# CPSW1_NUSS register map
Vendor: Texas Instruments
Peripheral module from a debugger description file (folder J721S2).
Registers are 32-bit, read-write, reset 0x0 unless marked. A register's access mark holds for its fields unless they carry their own. Offsets are as the file gives them; lines under a group give offsets from that group; [hi:lo] are bit positions; {n}, {i} and the like mark numbered series; 'fields as' and 'values as' point back to an identical list; <NAME> marks a mode.

## CPSW1_NUSS (part 1 of 2)
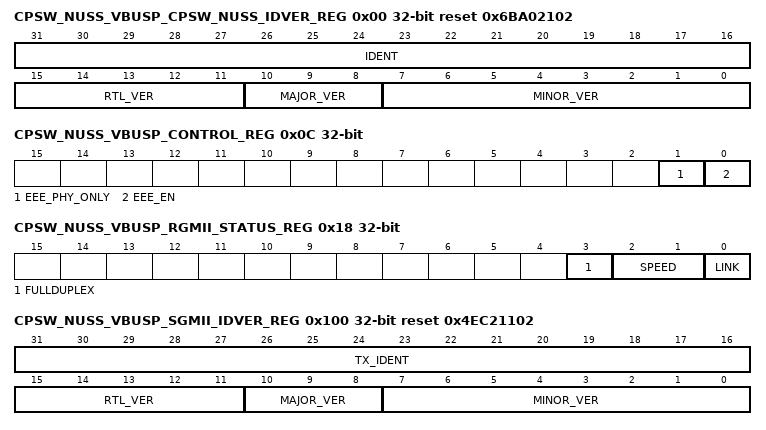
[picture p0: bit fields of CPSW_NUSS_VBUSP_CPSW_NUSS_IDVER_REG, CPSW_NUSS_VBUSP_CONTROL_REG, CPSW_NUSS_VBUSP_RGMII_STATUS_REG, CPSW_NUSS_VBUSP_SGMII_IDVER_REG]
0x00 CPSW_NUSS_VBUSP_CPSW_NUSS_IDVER_REG ro reset 0x6BA02102 — CPSW_NUSS ID Version Register
  [31:16] IDENT — Identification value
  [15:11] RTL_VER — RTL version value
  [10:8] MAJOR_VER — Major version value
  [7:0] MINOR_VER — Minor version value
0x04 CPSW_NUSS_VBUSP_SYNCE_COUNT_REG — CPSW_NUSS SYNCE Count Register
  [31:0] SYNCE_CNT — Sync E Count Value
0x08 CPSW_NUSS_VBUSP_SYNCE_MUX_REG — CPSW_NUSS Synce Mux Register
  [5:0] SYNCE_SEL — Sync E Select Value
0x0C CPSW_NUSS_VBUSP_CONTROL_REG — CPSW_NUSS Control Register
  [1] EEE_PHY_ONLY — Energy Efficient Enable Phy Only Mode: 0=The low power indicate state includes gating off the CPPI_GCLK to the CPSW, 1=The low power indicate state does not gate the clock to the CPSW
  [0] EEE_EN — Energy Efficient Ethernet Enable: 0=EEE is disabled, 1=EEE is enabled
0x10 CPSW_NUSS_VBUSP_SGMII_MODE_REG reset 0x1 — CPSW_NUSS SyncE Mux Register
  [0] SYNCE_SEL — SGMII_MODE Input
0x18 CPSW_NUSS_VBUSP_RGMII_STATUS_REG ro — CPSW_NUSS RGMII Status Register
  [3] FULLDUPLEX — Rgmii full dulex: 0=Half-duplex, 1=Full-duplex
  [2:1] SPEED — Rgmii speed: 00=10Mbps, 01=100Mbps, 10=1000Mbps, 11=reserved
  [0] LINK — Rgmii link indicator: 0=Link is down, 1=Link is up
0x1C CPSW_NUSS_VBUSP_SUBSSYSTEM_STATUS_REG ro — CPSW_NUSS Status Register
  [0] EEE_CLKSTOP_ACK — Energy Efficient Ethernet clockstop acknowledge from CPSW
0x100 CPSW_NUSS_VBUSP_SGMII_IDVER_REG ro reset 0x4EC21102 — SGMII IDVER register
  [31:16] TX_IDENT — Module value
  [15:11] RTL_VER — RTL version value
  [10:8] MAJOR_VER — Major version value
  [7:0] MINOR_VER — Minor version value
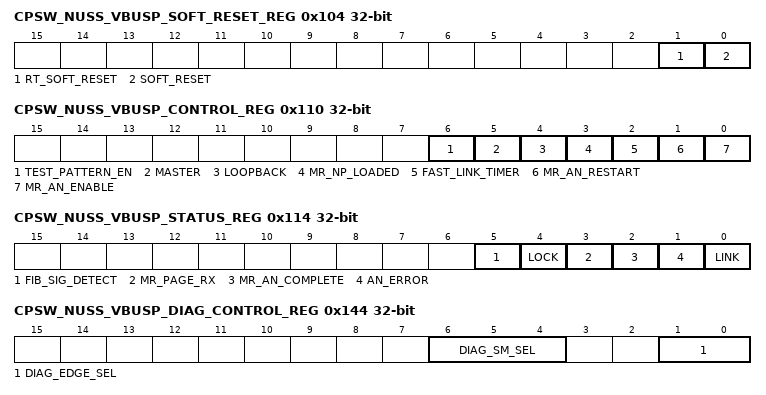
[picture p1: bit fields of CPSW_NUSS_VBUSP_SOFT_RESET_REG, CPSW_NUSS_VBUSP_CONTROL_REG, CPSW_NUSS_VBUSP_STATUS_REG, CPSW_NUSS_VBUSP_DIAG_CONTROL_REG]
0x104 CPSW_NUSS_VBUSP_SOFT_RESET_REG — SGMII Soft Reset Register
  [1] RT_SOFT_RESET — Transmit and receive software reset
  [0] SOFT_RESET — Software reset
0x110 CPSW_NUSS_VBUSP_CONTROL_REG — SGMII Control Register
  [6] TEST_PATTERN_EN — Test pattern enable
  [5] MASTER — Master mode
  [4] LOOPBACK — Loopback mode
  [3] MR_NP_LOADED — Next page loaded
  [2] FAST_LINK_TIMER
  [1] MR_AN_RESTART — Auto-negotiation restart
  [0] MR_AN_ENABLE — Auto-negotiation enable
0x114 CPSW_NUSS_VBUSP_STATUS_REG ro — SGMII Status Register
  [5] FIB_SIG_DETECT — Fiber signal detect
  [4] LOCK
  [3] MR_PAGE_RX — Next page received
  [2] MR_AN_COMPLETE — Auto-negotiation complete
  [1] AN_ERROR — Auto-negotiation error
  [0] LINK — Link indicator
0x118 CPSW_NUSS_VBUSP_MR_ADV_ABILITY_REG — SGMII MR Advertized Ability Register
  [15:0] MR_ADV_ABILITY — Advertised ability
0x11C CPSW_NUSS_VBUSP_MR_NP_TX_REG — SGMII Next Pate Transmit Register
  [15:0] MR_NP_TX — Next page transmit
0x120 CPSW_NUSS_VBUSP_MR_LP_ADV_ABILITY_REG ro — SGMII Link Partner Advertized Ability Register
  [15:0] MR_LP_ADV_ABILITY — Link partner advertised ability
0x124 CPSW_NUSS_VBUSP_MR_LP_NP_RX_REG ro — SGMII Link Partner Next Page Receive Register
  [15:0] MR_LP_NP_RX — Link Partner Next Page Received
0x130 CPSW_NUSS_VBUSP_TX_CFG_REG — SGMII Transmit Configuration Register
  [31:0] TX_CFG — Transmit configuration register output
0x134 CPSW_NUSS_VBUSP_RX_CFG_REG — SGMII Receive Configuration Register
  [31:0] RX_CFG — Receive configuration register output
0x138 CPSW_NUSS_VBUSP_AUX_CFG_REG — SGMII Auxiliary Configuration Register
  [31:0] AUX_CFG — Auxiliary configuration register output
0x140 CPSW_NUSS_VBUSP_DIAG_CLEAR_REG — SGMII Diagnostics Clear Register
  [0] DIAG_CLEAR — Diagnostics clear
0x144 CPSW_NUSS_VBUSP_DIAG_CONTROL_REG — SGMII Diagnostics Control Register
  [6:4] DIAG_SM_SEL — Diagnostic select
  [1:0] DIAG_EDGE_SEL — Diagnostics hold signals edge select
0x148 CPSW_NUSS_VBUSP_DIAG_STATUS_REG ro — SGMII Diagnostics Status Register
  [15:0] DIAG_STATUS — Diagnostics status
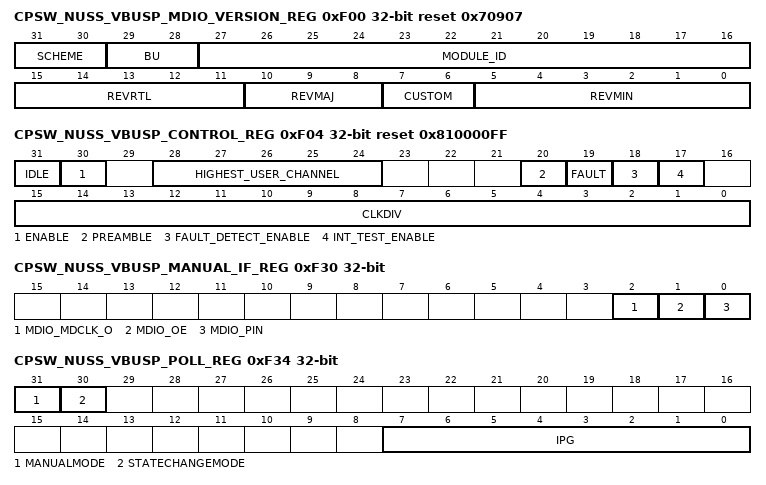
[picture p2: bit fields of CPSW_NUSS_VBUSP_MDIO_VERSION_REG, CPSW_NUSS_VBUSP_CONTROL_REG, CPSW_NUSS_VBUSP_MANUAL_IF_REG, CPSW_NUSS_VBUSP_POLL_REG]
0xF00 CPSW_NUSS_VBUSP_MDIO_VERSION_REG ro reset 0x70907 — MDIO Version Register
  [31:30] SCHEME
  [29:28] BU
  [27:16] MODULE_ID
  [15:11] REVRTL — RTL version
  [10:8] REVMAJ — Major version
  [7:6] CUSTOM — Custom version
  [5:0] REVMIN — Minor version
0xF04 CPSW_NUSS_VBUSP_CONTROL_REG access per field reset 0x810000FF — MDIO Control Register
  [31] IDLE ro — MDIO state machine idle
  [30] ENABLE rw — Enable control
  [28:24] HIGHEST_USER_CHANNEL ro
  [20] PREAMBLE rw — Preamble disable
  [19] FAULT rw — Fault indicator
  [18] FAULT_DETECT_ENABLE rw
  [17] INT_TEST_ENABLE rw — Interrupt test enable
  [15:0] CLKDIV rw — Clock divider
0xF08 CPSW_NUSS_VBUSP_ALIVE_REG — MDIO Alive Register
  [31:0] ALIVE — MDIO alive
0xF0C CPSW_NUSS_VBUSP_LINK_REG ro — MDIO Link Register
  [31:0] LINK — MDIO link state
0xF10 CPSW_NUSS_VBUSP_LINK_INT_RAW_REG — MDIO Link Interrupt Raw Register
  [1:0] LINKINTRAW — MDIO link change event raw value
0xF14 CPSW_NUSS_VBUSP_LINK_INT_MASKED_REG — MDIO Link Interrupt Masked Register
  [1:0] LINKINTMASKED — MDIO link change interrupt masked value
0xF18 CPSW_NUSS_VBUSP_LINK_INT_MASK_SET_REG — MDIO Link Interrupt Mask Set Register
  [0] LINKINTMASKSET — MDIO link interrupt mask set
0xF1C CPSW_NUSS_VBUSP_LINK_INT_MASK_CLEAR_REG — MDIO Link Interrupt Mask Clear Register
  [0] LINKINTMASKCLR — MDIO link interrupt mask clear
0xF20 CPSW_NUSS_VBUSP_USER_INT_RAW_REG — MDIO User Interrupt Raw Register
  [1:0] USERINTRAW — User interrupt raw
0xF24 CPSW_NUSS_VBUSP_USER_INT_MASKED_REG — MDIO User Interrupt Masked Register
  [1:0] USERINTMASKED — User interrupt masked
0xF28 CPSW_NUSS_VBUSP_USER_INT_MASK_SET_REG — MDIO User Interrupt Mask Set Register
  [1:0] USERINTMASKSET — MDIO user interrupt mask set
0xF2C CPSW_NUSS_VBUSP_USER_INT_MASK_CLEAR_REG — MDIO User Interrupt Mask Clear Register
  [1:0] USERINTMASKCLR — MDIO user interrupt mask clear
0xF30 CPSW_NUSS_VBUSP_MANUAL_IF_REG — MDIO Manual Interface Register
  [2] MDIO_MDCLK_O — MDIO Clock Output
  [1] MDIO_OE — MDIO Output Enable
  [0] MDIO_PIN
0xF34 CPSW_NUSS_VBUSP_POLL_REG — MDIO Poll Register
  [31] MANUALMODE — MDIO Manual Mode
  [30] STATECHANGEMODE — MDIO State Change Mode
  [7:0] IPG — MDIO IPG
0xF38 CPSW_NUSS_VBUSP_POLL_EN_REG reset 0xFFFFFFFF — MDIO Poll Enable Register
  [31:0] POLL_EN — MDIO Poll Enable
0xF3C CPSW_NUSS_VBUSP_CLAUS45_REG — MDIO Clause45 Register
  [31:0] CLAUSE45 — MDIO Clause 45
0xF40 CPSW_NUSS_VBUSP_USER_ADDR0_REG — MDIO Address 0 Register
  [15:0] USER_ADDR0 — MDIO USER Address 0
0xF44 CPSW_NUSS_VBUSP_USER_ADDR1_REG — MDIO Address 1 Register
  [15:0] USER_ADDR1 — MDIO USER Address 1
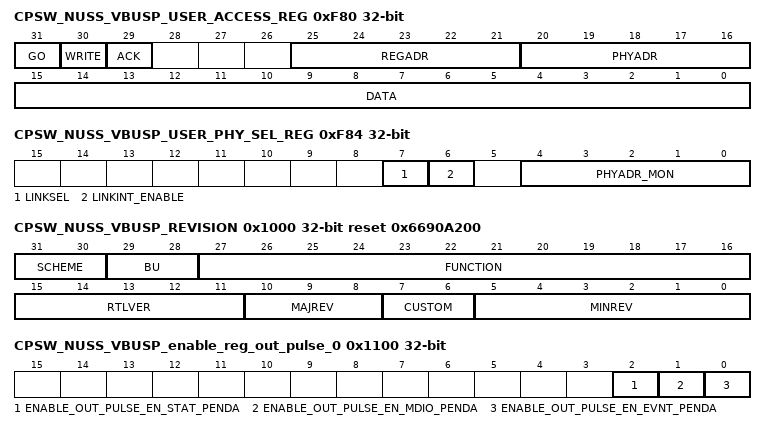
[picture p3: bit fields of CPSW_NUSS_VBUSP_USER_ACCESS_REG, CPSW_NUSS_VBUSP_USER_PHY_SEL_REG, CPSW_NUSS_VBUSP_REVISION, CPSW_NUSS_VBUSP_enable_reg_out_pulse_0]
0xF80 CPSW_NUSS_VBUSP_USER_ACCESS_REG — MDIO User Access Register
  [31] GO
  [30] WRITE
  [29] ACK — Acknowledge
  [25:21] REGADR — Register address
  [20:16] PHYADR — PHY address
  [15:0] DATA — User data
0xF84 CPSW_NUSS_VBUSP_USER_PHY_SEL_REG — MDIO User PHY Select Register
  [7] LINKSEL — Link status determination select
  [6] LINKINT_ENABLE — Link change interrupt enable
  [4:0] PHYADR_MON — PHY address whose link status is monitored
0x1000 CPSW_NUSS_VBUSP_REVISION ro reset 0x6690A200 — Revision Register
  [31:30] SCHEME
  [29:28] BU
  [27:16] FUNCTION — Module ID
  [15:11] RTLVER — RTL revisions
  [10:8] MAJREV — Major revision
  [7:6] CUSTOM — Custom revision
  [5:0] MINREV — Minor revision
0x1010 CPSW_NUSS_VBUSP_eoi_reg — End of Interrupt Register
  [7:0] EOI_VECTOR — End of Interrupt Vector
0x1014 CPSW_NUSS_VBUSP_intr_vector_reg ro — Interrupt Vector Register
  [31:0] INTR_VECTOR
0x1100 CPSW_NUSS_VBUSP_enable_reg_out_pulse_0 access not given — Enable Register 0
  [2] ENABLE_OUT_PULSE_EN_STAT_PENDA — Enable Set for out_pulse_en_stat_penda (access R/W1TS)
  [1] ENABLE_OUT_PULSE_EN_MDIO_PENDA — Enable Set for out_pulse_en_mdio_penda (access R/W1TS)
  [0] ENABLE_OUT_PULSE_EN_EVNT_PENDA — Enable Set for out_pulse_en_evnt_penda (access R/W1TS)
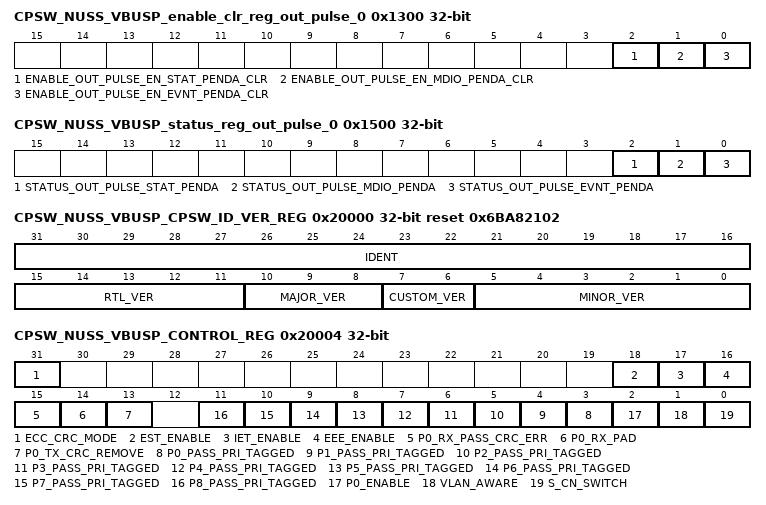
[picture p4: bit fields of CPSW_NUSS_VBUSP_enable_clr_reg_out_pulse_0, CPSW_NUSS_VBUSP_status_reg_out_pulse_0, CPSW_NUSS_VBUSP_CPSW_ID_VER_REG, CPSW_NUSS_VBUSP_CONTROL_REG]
0x1300 CPSW_NUSS_VBUSP_enable_clr_reg_out_pulse_0 access not given — Enable Clear Register 0
  [2] ENABLE_OUT_PULSE_EN_STAT_PENDA_CLR — Enable Clear for out_pulse_en_stat_penda (access R/W1TC)
  [1] ENABLE_OUT_PULSE_EN_MDIO_PENDA_CLR — Enable Clear for out_pulse_en_mdio_penda (access R/W1TC)
  [0] ENABLE_OUT_PULSE_EN_EVNT_PENDA_CLR — Enable Clear for out_pulse_en_evnt_penda (access R/W1TC)
0x1500 CPSW_NUSS_VBUSP_status_reg_out_pulse_0 ro — Status Register 0
  [2] STATUS_OUT_PULSE_STAT_PENDA — Status for out_pulse_en_stat_penda
  [1] STATUS_OUT_PULSE_MDIO_PENDA — Status for out_pulse_en_mdio_penda
  [0] STATUS_OUT_PULSE_EVNT_PENDA — Status for out_pulse_en_evnt_penda
0x1A80 CPSW_NUSS_VBUSP_intr_vector_reg_out_pulse ro — Interrupt Vector for out_pulse
  [31:0] INTR_VECTOR_OUT_PULSE — Interrupt Vector
0x20000 CPSW_NUSS_VBUSP_CPSW_ID_VER_REG ro reset 0x6BA82102 — CPSW ID Version
  [31:16] IDENT — Identification Value
  [15:11] RTL_VER — RTL Version Value
  [10:8] MAJOR_VER — Major Version Value
  [7:6] CUSTOM_VER — Custom Version Value
  [5:0] MINOR_VER — Minor Version Value
0x20004 CPSW_NUSS_VBUSP_CONTROL_REG — CPSW Switch Control
  [31] ECC_CRC_MODE
  [18] EST_ENABLE — Intersperced Express Traffic enable
  [17] IET_ENABLE — Intersperced Express Traffic enable
  [16] EEE_ENABLE — Energy Efficient Ethernet enable
  [15] P0_RX_PASS_CRC_ERR — Port 0 Pass Received CRC errors
  [14] P0_RX_PAD — Port 0 Receive Short Packet Pad
  [13] P0_TX_CRC_REMOVE — Port 0 Transmit CRC remove
  [n+3] P{n}_PASS_PRI_TAGGED (n=0..8) — Port {n} Pass Priority Tagged
  [2] P0_ENABLE — Port 0 Enable
  [1] VLAN_AWARE — VLAN Aware Mode
  [0] S_CN_SWITCH — VLAN Aware Mode
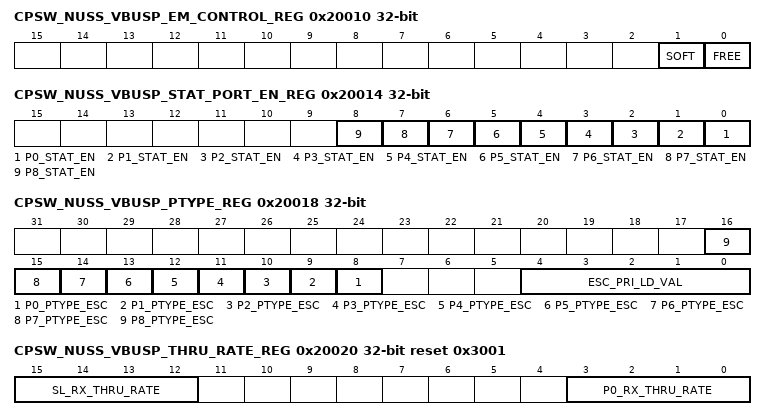
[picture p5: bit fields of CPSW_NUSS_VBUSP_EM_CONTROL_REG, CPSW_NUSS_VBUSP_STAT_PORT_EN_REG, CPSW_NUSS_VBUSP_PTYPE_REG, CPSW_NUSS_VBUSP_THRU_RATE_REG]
0x20010 CPSW_NUSS_VBUSP_EM_CONTROL_REG — CPSW Emulation Control
  [1] SOFT — Emulation Soft Bit
  [0] FREE — Emulation Free Bit
0x20014 CPSW_NUSS_VBUSP_STAT_PORT_EN_REG — CPSW Statistics Port Enable
  [n] P{n}_STAT_EN (n=0..8) — Port {n} Statistics Enable
0x20018 CPSW_NUSS_VBUSP_PTYPE_REG — CPSW Transmit Priority Type
  [n+8] P{n}_PTYPE_ESC (n=0..8) — Port {n} Priority Type Escalate
  [4:0] ESC_PRI_LD_VAL — Escalate Priority Load Value
0x2001C CPSW_NUSS_VBUSP_SOFT_IDLE_REG — CPSW Software Idle
  [0] SOFT_IDLE — Software Idle
0x20020 CPSW_NUSS_VBUSP_THRU_RATE_REG reset 0x3001 — CPSW Thru Rate
  [15:12] SL_RX_THRU_RATE — Switch FIFO receive through rate
  [3:0] P0_RX_THRU_RATE — CPPI FIFO receive through rate
0x20024 CPSW_NUSS_VBUSP_GAP_THRESH_REG reset 0xB — CPSW Transmit FIFO Short Gap Threshold
  [4:0] GAP_THRESH — Short Gap Threshold
0x20028 CPSW_NUSS_VBUSP_TX_START_WDS_REG reset 0x8 — CPSW Transmit FIFO Start Words
  [10:0] TX_START_WDS — FIFO Packet Transmit Start Words
0x2002C CPSW_NUSS_VBUSP_EEE_PRESCALE_REG — CPSW Energy Efficient Ethernet Prescale Value
  [11:0] EEE_PRESCALE — Energy Efficient Ethernet Pre-scale count load value
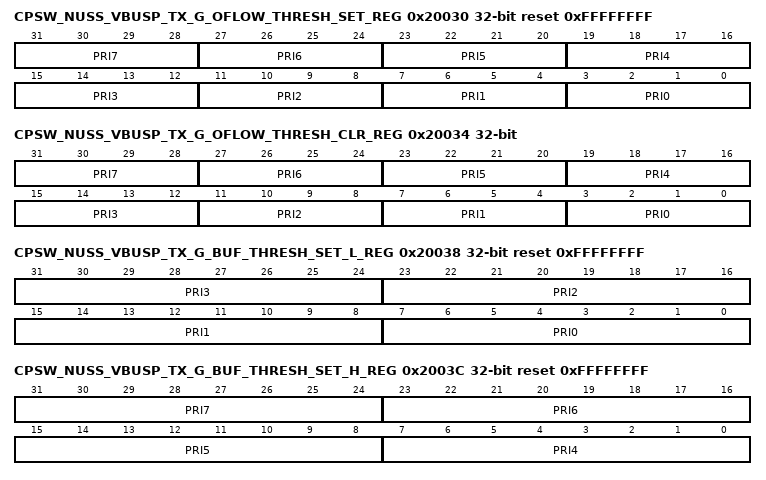
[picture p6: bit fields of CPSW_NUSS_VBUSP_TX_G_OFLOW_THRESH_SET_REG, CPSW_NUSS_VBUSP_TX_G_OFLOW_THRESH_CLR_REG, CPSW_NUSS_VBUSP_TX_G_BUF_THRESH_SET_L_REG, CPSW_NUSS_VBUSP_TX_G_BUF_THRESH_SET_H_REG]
0x20030 CPSW_NUSS_VBUSP_TX_G_OFLOW_THRESH_SET_REG reset 0xFFFFFFFF — CPSW PFC Tx Global Out Flow Threshold Set
  [4n+3:4n] PRI{n} (n=0..7) — Priority Based Flow Control Global Outflow Usage Threshold for Pri {n}
0x20034 CPSW_NUSS_VBUSP_TX_G_OFLOW_THRESH_CLR_REG — CPSW PFC Tx Global Out Flow Threshold Clear
  fields as CPSW_NUSS_VBUSP_TX_G_OFLOW_THRESH_SET_REG
0x20038 CPSW_NUSS_VBUSP_TX_G_BUF_THRESH_SET_L_REG reset 0xFFFFFFFF — CPSW PFC Global Tx Buffer Threshold Set Low
  [8n+7:8n] PRI{n} (n=0..3) — Priority Based Flow Control Global Buffer Usage Threshold for Priority {n}
0x2003C CPSW_NUSS_VBUSP_TX_G_BUF_THRESH_SET_H_REG reset 0xFFFFFFFF — CPSW PFC Global Tx Buffer Threshold Set High
  [8n-25:8n-32] PRI{n} (n=4..7) — Priority Based Flow Control Global Buffer Usage Threshold for Priority {n}
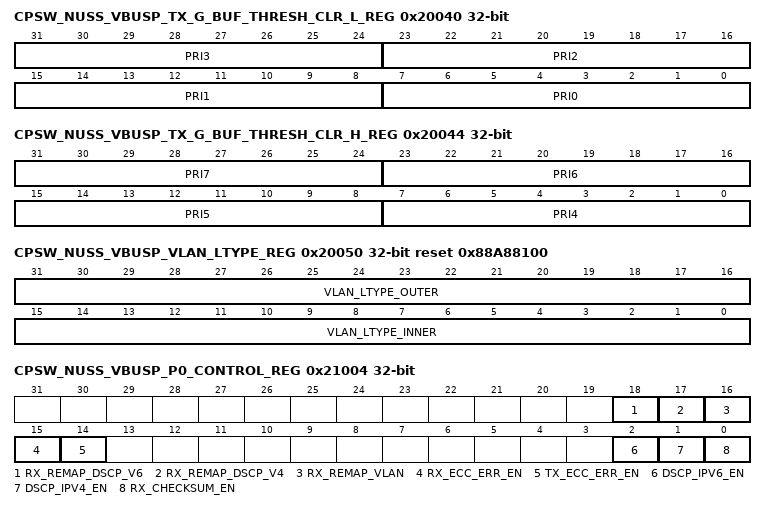
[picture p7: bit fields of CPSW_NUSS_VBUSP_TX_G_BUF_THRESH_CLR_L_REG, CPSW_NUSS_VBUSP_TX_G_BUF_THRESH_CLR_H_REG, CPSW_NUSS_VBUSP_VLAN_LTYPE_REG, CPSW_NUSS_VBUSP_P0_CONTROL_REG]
0x20040 CPSW_NUSS_VBUSP_TX_G_BUF_THRESH_CLR_L_REG — CPSW PFC Global Tx Buffer Threshold Clear Low
  fields as CPSW_NUSS_VBUSP_TX_G_BUF_THRESH_SET_L_REG
0x20044 CPSW_NUSS_VBUSP_TX_G_BUF_THRESH_CLR_H_REG — CPSW PFC Global Tx Buffer Threshold Clear High
  fields as CPSW_NUSS_VBUSP_TX_G_BUF_THRESH_SET_H_REG
0x20050 CPSW_NUSS_VBUSP_VLAN_LTYPE_REG reset 0x88A88100 — VLAN Length/type
  [31:16] VLAN_LTYPE_OUTER — Outer VLAN LType
  [15:0] VLAN_LTYPE_INNER — Inner VLAN LType
0x20054 CPSW_NUSS_VBUSP_EST_TS_DOMAIN_REG — Enhanced Scheduled Traffic Host Event Domain
  [7:0] EST_TS_DOMAIN
{0x20100+4i} CPSW_NUSS_VBUSP_TX_PRI{i}_MAXLEN_REG reset 0x7E8 (i=0..7) — Transmit Priority {i} Maximum Length
  [13:0] TX_PRI{i}_MAXLEN
0x21004 CPSW_NUSS_VBUSP_P0_CONTROL_REG — CPPI Port 0 Control
  [18] RX_REMAP_DSCP_V6 — Port 0 Remap DSCP_V6 Enable
  [17] RX_REMAP_DSCP_V4 — Port 0 Remap DSCP_V4 Enable
  [16] RX_REMAP_VLAN — Port 0 Remap VLAN Enable
  [15] RX_ECC_ERR_EN — Port 0 Receive ECC Error Enable
  [14] TX_ECC_ERR_EN — Port 0 Transmit ECC Error Enable
  [2] DSCP_IPV6_EN — Port 0 IPv6 DSCP enable
  [1] DSCP_IPV4_EN — Port 0 IPv4 DSCP enable
  [0] RX_CHECKSUM_EN — Port 0 Receive Checksum Enable
0x21008 CPSW_NUSS_VBUSP_P0_FLOW_ID_OFFSET_REG — CPPI Port 0 Flow ID Offset
  [13:0] VALUE — This value is added to the thread/Flow_ID in CPPI transmit PSI Info Word 0
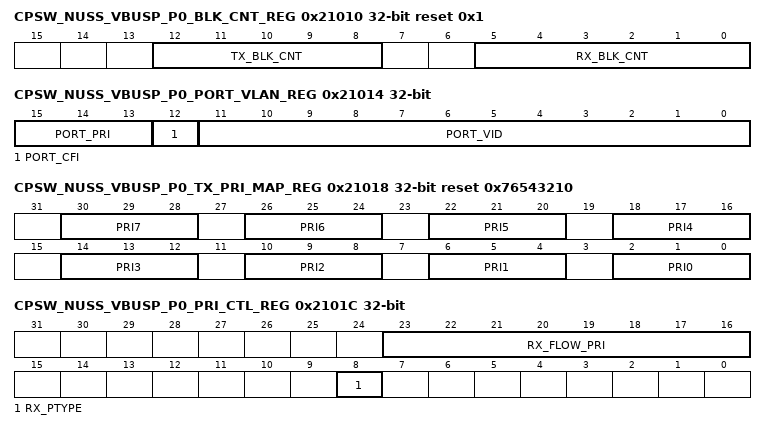
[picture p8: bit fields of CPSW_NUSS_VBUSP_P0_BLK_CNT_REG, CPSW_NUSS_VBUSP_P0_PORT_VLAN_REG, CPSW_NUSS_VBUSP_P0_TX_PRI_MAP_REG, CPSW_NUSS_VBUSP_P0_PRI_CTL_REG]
0x21010 CPSW_NUSS_VBUSP_P0_BLK_CNT_REG ro reset 0x1 — CPPI Port 0 FIFO Block Usage Count
  [12:8] TX_BLK_CNT — Port 0 Transmit Block Count Usage
  [5:0] RX_BLK_CNT — Port 0 Receive Block Count Usage
0x21014 CPSW_NUSS_VBUSP_P0_PORT_VLAN_REG — CPPI Port 0 VLAN
  [15:13] PORT_PRI — Port VLAN Priority
  [12] PORT_CFI — Port CFI bit
  [11:0] PORT_VID — Port VLAN ID
0x21018 CPSW_NUSS_VBUSP_P0_TX_PRI_MAP_REG reset 0x76543210 — CPPI Port 0 Tx Header Pri to Switch Pri Mapping
  [4n+2:4n] PRI{n} (n=0..7) — Priority {n}
0x2101C CPSW_NUSS_VBUSP_P0_PRI_CTL_REG — CPPI Port 0 Priority Control
  [23:16] RX_FLOW_PRI — Receive Priority Based Flow Control Enable (per priority)
  [8] RX_PTYPE — Receive Priority Type
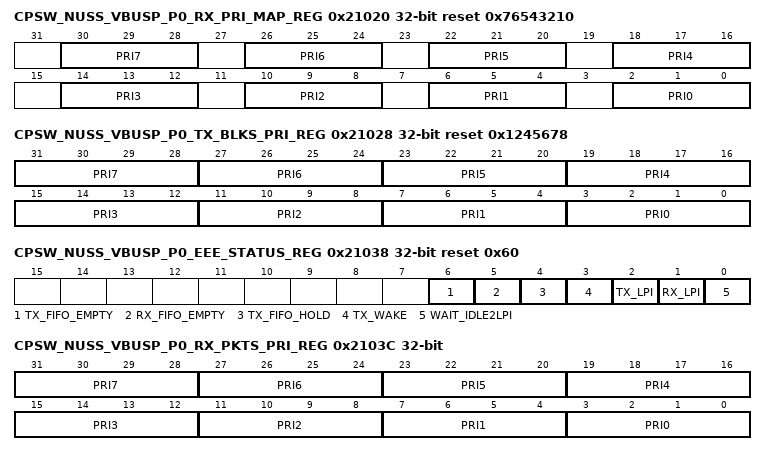
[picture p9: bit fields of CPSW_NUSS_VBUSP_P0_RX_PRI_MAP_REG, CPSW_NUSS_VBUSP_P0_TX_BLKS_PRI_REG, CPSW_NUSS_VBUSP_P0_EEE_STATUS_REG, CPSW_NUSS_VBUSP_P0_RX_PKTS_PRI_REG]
0x21020 CPSW_NUSS_VBUSP_P0_RX_PRI_MAP_REG reset 0x76543210 — CPPI Port 0 RX Pkt Pri to Header Pri Map
  [4n+2:4n] PRI{n} (n=0..7) — Priority {n}
0x21024 CPSW_NUSS_VBUSP_P0_RX_MAXLEN_REG reset 0x5EE — CPPI Port 0 Receive Frame Max Length
  [13:0] RX_MAXLEN — Rx Maximum Frame Length
0x21028 CPSW_NUSS_VBUSP_P0_TX_BLKS_PRI_REG reset 0x1245678 — CPPI Port 0 Transmit Block Sub Per Priority
  [4n+3:4n] PRI{n} (n=0..7) — Priority {n} Port Transmit Blocks
0x21030 CPSW_NUSS_VBUSP_P0_IDLE2LPI_REG — Port 0 EEE Idle to LPI counter
  [23:0] COUNT — Port 0 EEE Idle to LPI counter load value
0x21034 CPSW_NUSS_VBUSP_P0_LPI2WAKE_REG — Port 0 EEE LPI to wake counter
  [23:0] COUNT — Port 0 EEE LPI to wake counter load value
0x21038 CPSW_NUSS_VBUSP_P0_EEE_STATUS_REG ro reset 0x60 — Port 0 EEE status
  [6] TX_FIFO_EMPTY — CPPI port 0 transmit FIFO (switch egress) is empty - contains no packets
  [5] RX_FIFO_EMPTY — CPPI port 0 receive FIFO (switch ingress) is empty - contains no packets
  [4] TX_FIFO_HOLD — CPPI port 0 transmit FIFO hold - asserted in the LPI state and during the LPI2WAKE count time
  [3] TX_WAKE — CPPI port 0 transmit wakeup - asserted in the transmit LPI2WAKE count time
  [2] TX_LPI — CPPI port 0 transmit LPI state - asserted when the port 0 transmit is in the LPI state
  [1] RX_LPI — CPPI port 0 receive LPI state - asserted when the port 0 receive is in the LPI state
  [0] WAIT_IDLE2LPI — CPPI port 0 wait idle to LPI - asserted when port 0 is counting the IDLE2LPI time
0x2103C CPSW_NUSS_VBUSP_P0_RX_PKTS_PRI_REG — CPPI Port Receive Packets per priority
  [4n+3:4n] PRI{n} (n=0..7) — Priority {n} Port Port 0 Receive Packets
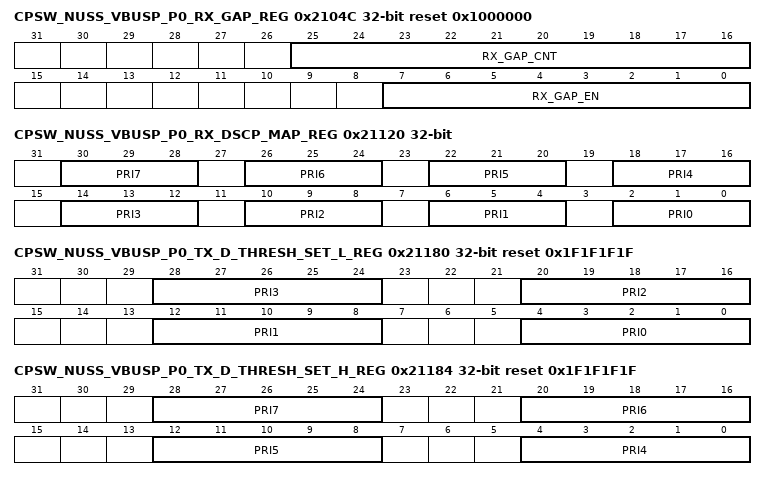
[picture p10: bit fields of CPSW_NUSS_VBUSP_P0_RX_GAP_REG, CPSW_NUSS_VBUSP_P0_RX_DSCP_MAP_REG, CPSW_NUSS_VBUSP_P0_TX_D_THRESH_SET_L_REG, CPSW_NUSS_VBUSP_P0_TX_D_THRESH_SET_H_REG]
0x2104C CPSW_NUSS_VBUSP_P0_RX_GAP_REG reset 0x1000000 — Port 0 Receive Gap Register
  [25:16] RX_GAP_CNT — Port 0 Receive Gap Count
  [7:0] RX_GAP_EN — Port 0 Receive Gap Enable
0x21050 CPSW_NUSS_VBUSP_P0_FIFO_STATUS_REG ro — Port 0 FIFO Status
  [7:0] TX_PRI_ACTIVE
0x21120 CPSW_NUSS_VBUSP_P0_RX_DSCP_MAP_REG — CPPI Port 0 Receive IPV4/IPV6 DSCP Map N
  [4n+2:4n] PRI{n} (n=0..7) — A DSCP IPV4/V6 packet TOS of N*8+{n} is mapped to this received priority
0x21140 CPSW_NUSS_VBUSP_P0_PRI_CIR_REG — CPPI Port 0 Rx Priority P Committed Information Rate
  [27:0] PRI_CIR — Priority N CIR
0x21160 CPSW_NUSS_VBUSP_P0_PRI_EIR_REG — CPPI Port 0 Rx Priority P Excess Information Rate
  [27:0] PRI_EIR — Priority N EIR
0x21180 CPSW_NUSS_VBUSP_P0_TX_D_THRESH_SET_L_REG reset 0x1F1F1F1F — CPPI Port 0 Tx PFC Destination Threshold Set Low
  [8n+4:8n] PRI{n} (n=0..3) — Port Priority Based Flow Control Threshold Set Value for Priority {n}
0x21184 CPSW_NUSS_VBUSP_P0_TX_D_THRESH_SET_H_REG reset 0x1F1F1F1F — CPPI Port 0 Tx PFC Destination Threshold Set High
  [8n-28:8n-32] PRI{n} (n=4..7) — Port Priority Based Flow Control Threshold Set Value for Priority {n}
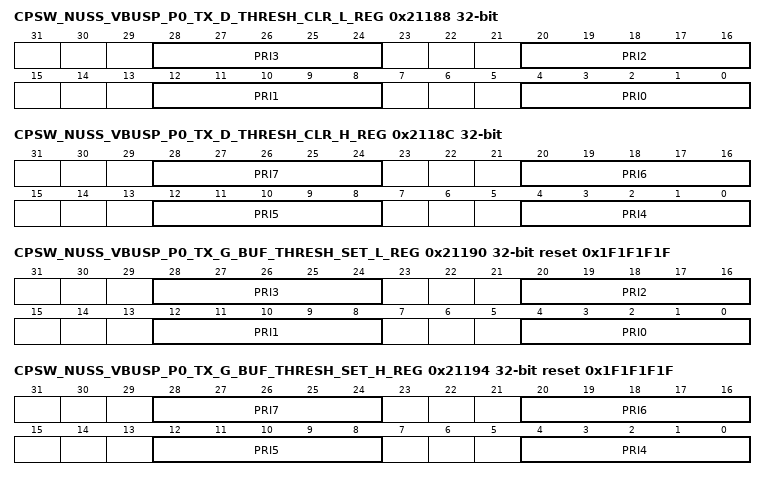
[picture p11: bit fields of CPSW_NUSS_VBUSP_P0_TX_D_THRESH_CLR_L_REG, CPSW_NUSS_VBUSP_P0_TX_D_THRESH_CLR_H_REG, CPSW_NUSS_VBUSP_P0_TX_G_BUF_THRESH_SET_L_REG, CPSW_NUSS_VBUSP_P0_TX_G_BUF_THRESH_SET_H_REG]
0x21188 CPSW_NUSS_VBUSP_P0_TX_D_THRESH_CLR_L_REG — CPPI Port 0 Tx PFC Destination Threshold Clr Low
  [8n+4:8n] PRI{n} (n=0..3) — Port Priority Based Flow Control Threshold Clear Value for Priority {n}
0x2118C CPSW_NUSS_VBUSP_P0_TX_D_THRESH_CLR_H_REG — CPPI Port 0 Tx PFC Destination Threshold Clr High
  [8n-28:8n-32] PRI{n} (n=4..7) — Port Priority Based Flow Control Threshold Clear Value for Priority {n}
0x21190 CPSW_NUSS_VBUSP_P0_TX_G_BUF_THRESH_SET_L_REG reset 0x1F1F1F1F — CPPI Port 0 Tx PFC Global Buffer Threshold Set Low
  fields as CPSW_NUSS_VBUSP_P0_TX_D_THRESH_SET_L_REG
0x21194 CPSW_NUSS_VBUSP_P0_TX_G_BUF_THRESH_SET_H_REG reset 0x1F1F1F1F — CPPI Port 0 Tx PFC Global Buffer Threshold Set High
  fields as CPSW_NUSS_VBUSP_P0_TX_D_THRESH_SET_H_REG
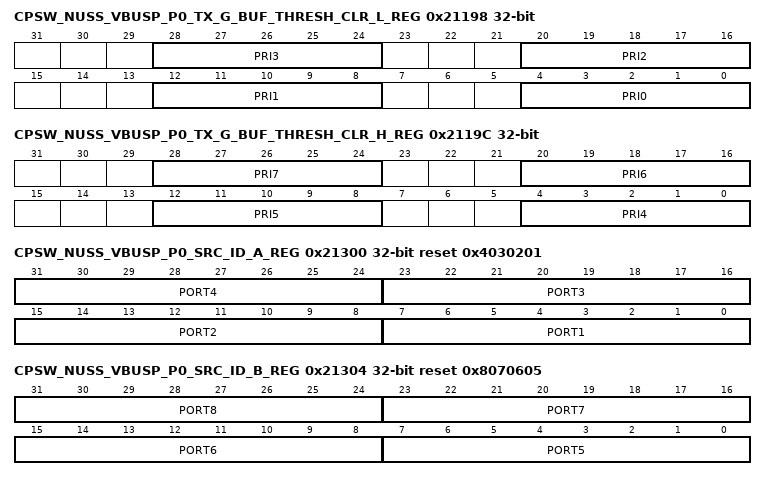
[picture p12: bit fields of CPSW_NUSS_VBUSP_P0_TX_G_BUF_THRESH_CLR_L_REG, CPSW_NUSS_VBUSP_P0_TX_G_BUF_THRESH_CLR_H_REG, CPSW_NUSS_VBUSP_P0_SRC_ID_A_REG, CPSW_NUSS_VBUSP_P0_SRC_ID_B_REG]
0x21198 CPSW_NUSS_VBUSP_P0_TX_G_BUF_THRESH_CLR_L_REG — CPPI Port 0 Tx PFC Global Buffer Threshold Clr Low
  fields as CPSW_NUSS_VBUSP_P0_TX_D_THRESH_CLR_L_REG
0x2119C CPSW_NUSS_VBUSP_P0_TX_G_BUF_THRESH_CLR_H_REG — CPPI Port 0 Tx PFC Global Buffer Threshold Clr High
  fields as CPSW_NUSS_VBUSP_P0_TX_D_THRESH_CLR_H_REG
0x21300 CPSW_NUSS_VBUSP_P0_SRC_ID_A_REG reset 0x4030201 — CPPI Port 0 CPPI Source ID A
  [8n-1:8n-8] PORT{n} (n=1..4) — Port {n} CPPI Info Word0 Source ID Value
0x21304 CPSW_NUSS_VBUSP_P0_SRC_ID_B_REG reset 0x8070605 — CPPI Port 0 CPPI Source ID B
  [8n-33:8n-40] PORT{n} (n=5..8) — Port {n} CPPI Info Word0 Source ID Value
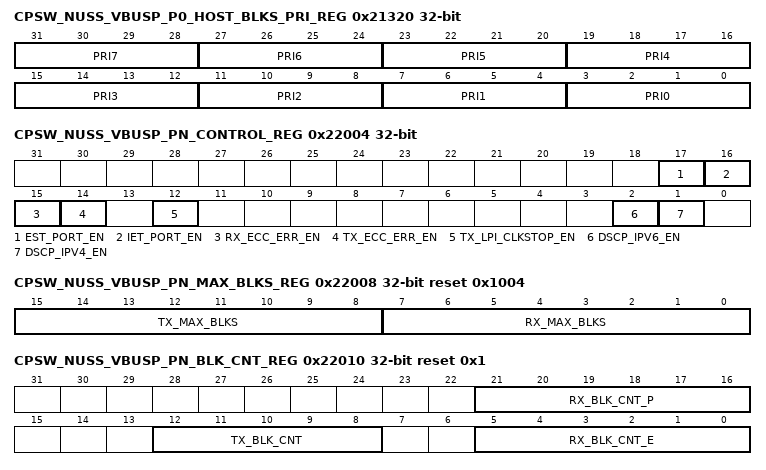
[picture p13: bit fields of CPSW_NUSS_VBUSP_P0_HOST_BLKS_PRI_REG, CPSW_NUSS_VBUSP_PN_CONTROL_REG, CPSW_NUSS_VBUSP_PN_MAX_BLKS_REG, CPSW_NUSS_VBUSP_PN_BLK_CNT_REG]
0x21320 CPSW_NUSS_VBUSP_P0_HOST_BLKS_PRI_REG — CPPI Port 0 Host Blocks Priority
  [4n+3:4n] PRI{n} (n=0..7) — Priority {n} Host Blocks
0x22000 CPSW_NUSS_VBUSP_PN_RESERVED_REG ro — Reserved
0x22004 CPSW_NUSS_VBUSP_PN_CONTROL_REG — Enet Port N Control
  [17] EST_PORT_EN — EST Port Enable
  [16] IET_PORT_EN — IET Port Enable
  [15] RX_ECC_ERR_EN — Port 0 Receive ECC Error Enable
  [14] TX_ECC_ERR_EN — Port 0 Transmit ECC Error Enable
  [12] TX_LPI_CLKSTOP_EN — Transmit LPI clockstop enable
  [2] DSCP_IPV6_EN — IPv6 DSCP enable
  [1] DSCP_IPV4_EN — IPv4 DSCP enable
0x22008 CPSW_NUSS_VBUSP_PN_MAX_BLKS_REG reset 0x1004 — Enet Port N FIFO Max Blocks
  [15:8] TX_MAX_BLKS — Transmit FIFO maximum blocks
  [7:0] RX_MAX_BLKS — Receive FIFO maximum blocks
0x22010 CPSW_NUSS_VBUSP_PN_BLK_CNT_REG ro reset 0x1 — Enet Port N FIFO Block Usage Count
  [21:16] RX_BLK_CNT_P — Receive Prempt Queue Block Count Usage
  [12:8] TX_BLK_CNT — Transmit Block Count Usage
  [5:0] RX_BLK_CNT_E — Receive Block Count Usage
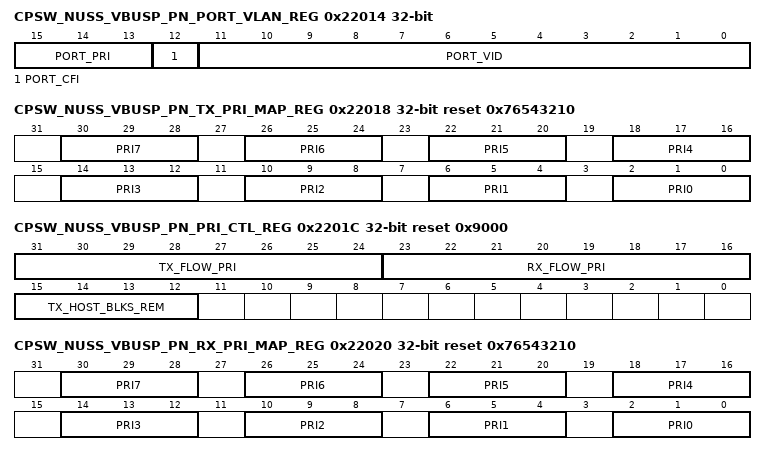
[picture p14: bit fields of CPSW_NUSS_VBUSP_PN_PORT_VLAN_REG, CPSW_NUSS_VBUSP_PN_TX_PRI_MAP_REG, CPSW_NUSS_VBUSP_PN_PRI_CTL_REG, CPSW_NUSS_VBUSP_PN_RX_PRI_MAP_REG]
0x22014 CPSW_NUSS_VBUSP_PN_PORT_VLAN_REG — Enet Port N VLAN
  fields as CPSW_NUSS_VBUSP_P0_PORT_VLAN_REG
0x22018 CPSW_NUSS_VBUSP_PN_TX_PRI_MAP_REG reset 0x76543210 — Enet Port N Tx Header Pri to Switch Pri Mapping
  [4n+2:4n] PRI{n} (n=0..7) — Priority {n}
0x2201C CPSW_NUSS_VBUSP_PN_PRI_CTL_REG reset 0x9000 — Enet Port N Priority Control
  [31:24] TX_FLOW_PRI — Transmit Priority Based Flow Control Enable (per priority)
  [23:16] RX_FLOW_PRI — Receive Priority Based Flow Control Enable (per priority)
  [15:12] TX_HOST_BLKS_REM — Transmit FIFO Blocks that must be free before a non rate-limited CPPI Port 0 receive thread can begin sending a packet
0x22020 CPSW_NUSS_VBUSP_PN_RX_PRI_MAP_REG reset 0x76543210 — Enet Port N RX Pkt Pri to Header Pri Map
  [4n+2:4n] PRI{n} (n=0..7) — Priority {n}
0x22024 CPSW_NUSS_VBUSP_PN_RX_MAXLEN_REG reset 0x5EE — Enet Port N Receive Frame Max Length
  [13:0] RX_MAXLEN — Rx Maximum Frame Length
0x22028 CPSW_NUSS_VBUSP_PN_TX_BLKS_PRI_REG reset 0x1245678 — Enet Port N Transmit Block Sub Per Priority
  [4n+3:4n] PRI{n} (n=0..7) — Priority {n} Port Transmit Blocks
0x2202C CPSW_NUSS_VBUSP_PN_RX_FLOW_THRESH_REG reset 0x40 — Enet MAC Receive Flow Threshold in Receive Buffer Words
  [8:0] COUNT — Receive Flow Threshold in Words
0x22030 CPSW_NUSS_VBUSP_PN_IDLE2LPI_REG — Enet Port N EEE Idle to LPI counter
  [23:0] COUNT — EEE Idle to LPI counter load value
0x22034 CPSW_NUSS_VBUSP_PN_LPI2WAKE_REG — Enet Port N EEE LPI to wake counter
  [23:0] COUNT — EEE LPI to wake counter load value
0x22038 CPSW_NUSS_VBUSP_PN_EEE_STATUS_REG ro reset 0x62 — Enet Port N EEE status
  [6] TX_FIFO_EMPTY — Transmit FIFO (switch egress) is empty - contains no packets
  [5] RX_FIFO_EMPTY — Receive FIFO (switch ingress) is empty - contains no packets
  [4] TX_FIFO_HOLD — Transmit FIFO hold - asserted in the LPI state and during the LPI2WAKE count time
  [3] TX_WAKE — Transmit wakeup - asserted in the transmit LPI2WAKE count time
  [2] TX_LPI — Transmit LPI state - asserted when the port 0 transmit is in the LPI state
  [1] RX_LPI — Receive LPI state - asserted when the port 0 receive is in the LPI state
  [0] WAIT_IDLE2LPI — CPPI port 0 wait idle to LPI - asserted when port 0 is counting the IDLE2LPI time
0x22040 CPSW_NUSS_VBUSP_PN_IET_CONTROL_REG reset 0x8 — Enet Port N IET Control
  [23:16] MAC_PREMPT — IET MAC Fragment Size
  [10:8] MAC_ADDFRAGSIZE — IET MAC Fragment Size
  [3] MAC_LINKFAIL — IET MAC LINK Fail Reset
  [2] MAC_DISABLEVERIFY — IET MAC Disable Verify
  [1] MAC_HOLD — IET MAC HOLD
  [0] MAC_PENABLE — IET MAC Penable
0x22044 CPSW_NUSS_VBUSP_PN_IET_STATUS_REG ro — Enet Port N IET Status
  [3] MAC_VERIFY_ERR — IET MAC VERIFY ERROR
  [2] MAC_RESPOND_ERR — IET MAC RESPONSE ERROR
  [1] MAC_VERIFY_FAIL — IET MAC VERIFY FAIL
  [0] MAC_VERIFIED — IET MAC VERIFIED
0x22048 CPSW_NUSS_VBUSP_PN_IET_VERIFY_REG reset 0x1312D0 — Enet Port N IET VERIFY
  [23:0] MAC_VERIFY_CNT — IET MAC VERIFY COUNT
0x22050 CPSW_NUSS_VBUSP_PN_FIFO_STATUS_REG ro reset 0xFF00 — Enet Port N FIFO STATUS
  [18] EST_BUFACT — Transmit FIFO EST Buffer Active
  [17] EST_ADD_ERR — Transmit FIFO EST Address Error
  [16] EST_CNT_ERR — Transmit FIFO EST Count Error
  [15:8] TX_E_MAC_ALLOW — Transmit FIFO Express Queue Priority Allow
  [7:0] TX_PRI_ACTIVE — Transmit FIFO Priority Active
0x22060 CPSW_NUSS_VBUSP_PN_EST_CONTROL_REG — Enet Port N EST CONTROL
  [25:16] EST_FILL_MARGIN — Transmit FIFO EST Fill Margin
  [15:9] EST_PREMPT_COMP — Transmit FIFO EST Prempt Comparision Value
  [8] EST_FILL_EN — Transmit FIFO EST Fill Enable
  [7:5] EST_TS_PRI — Transmit FIFO EST TimeStamp Priority
  [4] EST_TS_ONEPRI — Transmit FIFO EST TimeStamp One Priority
  [3] EST_TS_FIRST — Transmit FIFO EST TimeStamp First Express Packet
  [2] EST_TS_EN — Transmit FIFO EST TimeStamp Enable
  [1] EST_BUFSEL — Transmit FIFO EST Buffer Select
  [0] EST_ONEBUF — Transmit FIFO EST One Buffer
0x22120 CPSW_NUSS_VBUSP_PN_RX_DSCP_MAP_REG — Enet Port N Receive IPV4/IPV6 DSCP Map M
  fields as CPSW_NUSS_VBUSP_P0_RX_DSCP_MAP_REG
0x22140 CPSW_NUSS_VBUSP_PN_PRI_CIR_REG — Enet Port N Rx Priority P Committed Information Rate Value
  [27:0] PRI_CIR — Priority N committed information rate
0x22160 CPSW_NUSS_VBUSP_PN_PRI_EIR_REG — Enet Port N Rx Priority P Excess Informatoin Rate Value
  [27:0] PRI_EIR — Priority N Excess Information Rate count
0x22180 CPSW_NUSS_VBUSP_PN_TX_D_THRESH_SET_L_REG reset 0x1F1F1F1F — Enet Port N Tx PFC Destination Threshold Set Low
  fields as CPSW_NUSS_VBUSP_P0_TX_D_THRESH_SET_L_REG
0x22184 CPSW_NUSS_VBUSP_PN_TX_D_THRESH_SET_H_REG reset 0x1F1F1F1F — Enet Port N Tx PFC Destination Threshold Set High
  fields as CPSW_NUSS_VBUSP_P0_TX_D_THRESH_SET_H_REG
0x22188 CPSW_NUSS_VBUSP_PN_TX_D_THRESH_CLR_L_REG — Enet Port N Tx PFC Destination Threshold Clr Low
  fields as CPSW_NUSS_VBUSP_P0_TX_D_THRESH_CLR_L_REG
0x2218C CPSW_NUSS_VBUSP_PN_TX_D_THRESH_CLR_H_REG — Enet Port N Tx PFC Destination Threshold Clr High
  fields as CPSW_NUSS_VBUSP_P0_TX_D_THRESH_CLR_H_REG
0x22190 CPSW_NUSS_VBUSP_PN_TX_G_BUF_THRESH_SET_L_REG reset 0x1F1F1F1F — Enet Port N Tx PFC Global Buffer Threshold Set Low
  fields as CPSW_NUSS_VBUSP_P0_TX_D_THRESH_SET_L_REG
0x22194 CPSW_NUSS_VBUSP_PN_TX_G_BUF_THRESH_SET_H_REG reset 0x1F1F1F1F — Enet Port N Tx PFC Global Buffer Threshold Set High
  fields as CPSW_NUSS_VBUSP_P0_TX_D_THRESH_SET_H_REG
0x22198 CPSW_NUSS_VBUSP_PN_TX_G_BUF_THRESH_CLR_L_REG — Enet Port N Tx PFC Global Buffer Threshold Clr Low
  fields as CPSW_NUSS_VBUSP_P0_TX_D_THRESH_CLR_L_REG
0x2219C CPSW_NUSS_VBUSP_PN_TX_G_BUF_THRESH_CLR_H_REG — Enet Port N Tx PFC Global Buffer Threshold Clr High
  fields as CPSW_NUSS_VBUSP_P0_TX_D_THRESH_CLR_H_REG
0x22300 CPSW_NUSS_VBUSP_PN_TX_D_OFLOW_ADDVAL_L_REG — Enet Port N Tx Destination Out Flow Add Values Low
  [8n+4:8n] PRI{n} (n=0..3) — Port PFC Destination Based Out Flow Add Value for Priority {n}
0x22304 CPSW_NUSS_VBUSP_PN_TX_D_OFLOW_ADDVAL_H_REG — Enet Port N Tx Destination Out Flow Add Values High
  [8n-28:8n-32] PRI{n} (n=4..7) — Port PFC Destination Based Out Flow Add Value for Priority {n}
0x22308 CPSW_NUSS_VBUSP_PN_SA_L_REG — Enet Port N Tx Pause Frame Source Address Low
  [15:8] MACSRCADDR_7_0 — Source Address Lower 8 bits
  [7:0] MACSRCADDR_15_8 — Source Address bits 15:8
0x2230C CPSW_NUSS_VBUSP_PN_SA_H_REG — Enet Port N Tx Pause Frame Source Address High
  [31:24] MACSRCADDR_23_16 — Source Address bits 23:16
  [23:16] MACSRCADDR_31_24 — Source Address bits 31:24
  [15:8] MACSRCADDR_39_32 — Source Address bits 39:32
  [7:0] MACSRCADDR_47_40 — Source Address bits 47:40
0x22310 CPSW_NUSS_VBUSP_PN_TS_CTL_REG — Enet Port N Time Sync Control
  [31:16] TS_MSG_TYPE_EN — Time Sync Message Type Enable
  [11] TS_TX_HOST_TS_EN — Time Sync Transmit Host Time Stamp Enable
  [10] TS_TX_ANNEX_E_EN — Time Synce Transmit Annex E Enable
  [9] TS_RX_ANNEX_E_EN — Time Synce Receive Annex E Enable
  [8] TS_LTYPE2_EN — Time Sync LTYPE 2 enable transmit and receive
  [7] TS_TX_ANNEX_D_EN — Time Synce Transmit Annex D Enable
  [6] TS_TX_VLAN_LTYPE2_EN — Time Sync Transmit VLAN LTYPE 2 enable
  [5] TS_TX_VLAN_LTYPE1_EN — Time Sync Transmit VLAN LTYPE 1 enable
  [4] TS_TX_ANNEX_F_EN — Time Synce Transmit Annex F Enable
  [3] TS_RX_ANNEX_D_EN — Time Synce Receive Annex D Enable
  [2] TS_RX_VLAN_LTYPE2_EN — Time Sync Receive VLAN LTYPE 2 enable
  [1] TS_RX_VLAN_LTYPE1_EN — Time Sync Receive VLAN LTYPE 1 enable
  [0] TS_RX_ANNEX_F_EN — Time Synce Receive Annex F Enable
0x22314 CPSW_NUSS_VBUSP_PN_TS_SEQ_LTYPE_REG reset 0x1E0000 — Enet Port N Time Sync LTYPE (and SEQ_ID_OFFSET)
  [21:16] TS_SEQ_ID_OFFSET — Time Sync Sequence ID Offset
  [15:0] TS_LTYPE1 — Time Sync LTYPE1
0x22318 CPSW_NUSS_VBUSP_PN_TS_VLAN_LTYPE_REG — Enet Port N Time Sync VLAN2 and VLAN2
  [31:16] TS_VLAN_LTYPE2 — Time Sync VLAN LTYPE2
  [15:0] TS_VLAN_LTYPE1 — Time Sync VLAN LTYPE1
0x2231C CPSW_NUSS_VBUSP_PN_TS_CTL_LTYPE2_REG — Enet Port N Time Sync Control and LTYPE 2
  [24] TS_UNI_EN — Time Sync Unicast Enable
  [23] TS_TTL_NONZERO — Time Sync Time to Live Non-zero Enable
  [22] TS_320 — Time Sync Destination IP Address 320 Enable
  [21] TS_319 — Time Sync Destination IP Address 319 Enable
  [n-112] TS_{n} (n=129..132) — Time Sync Destination IP Address {n} Enable
  [16] TS_107 — Time Sync Destination IP Address 107 Enable
  [15:0] TS_LTYPE2 — Time Sync LTYPE2
0x22320 CPSW_NUSS_VBUSP_PN_TS_CTL2_REG reset 0x40000 — Enet Port N Time Sync Control 2
  [21:16] TS_DOMAIN_OFFSET — Time Sync Domain Offset
  [15:0] TS_MCAST_TYPE_EN — Time Sync Multicast Destination Address Type Enable
0x22330 CPSW_NUSS_VBUSP_PN_MAC_CONTROL_REG — Enet Port N Mac Control
  [24] RX_CMF_EN — RX Copy MAC Control Frames Enable
  [23] RX_CSF_EN — RX Copy Short Frames Enable
  [22] RX_CEF_EN — RX Copy Error Frames Enable
  [21] TX_SHORT_GAP_LIM_EN — Transmit Short Gap Limit Enable
  [20] EXT_TX_FLOW_EN — External Transmit Flow Control Enable
  [19] EXT_RX_FLOW_EN — External Receive Flow Control Enable
  [18] CTL_EN — Control Enable
  [17] GIG_FORCE — Gigabit Mode Force
  [16] IFCTL_B — Interface Control B
  [15] IFCTL_A — Interface Control A
  [12] CRC_TYPE — Port CRC Type
  [11] CMD_IDLE — Command Idle
  [10] TX_SHORT_GAP_ENABLE — Transmit Short Gap Enable
  [7] GIG — Gigabit Mode
  [6] TX_PACE — Transmit Pacing Enable
  [5] GMII_EN — GMII Enable
  [4] TX_FLOW_EN — Transmit Flow Control Enable
  [3] RX_FLOW_EN — Receive Flow Control Enable
  [2] MTEST — Manufacturing Test Mode
  [1] LOOPBACK — Loop Back Mode
  [0] FULLDUPLEX — Full Duplex mode
0x22334 CPSW_NUSS_VBUSP_PN_MAC_STATUS_REG ro reset 0xF0000000 — Enet Port N Mac Status
  [31] IDLE — cpxmac_sl IDLE
  [30] E_IDLE — cpxmac_sl IDLE
  [29] P_IDLE — cpxmac_sl IDLE
  [28] TX_IDLE — cpxmac_sl IDLE
  [27] TORF — Top of receive FIFO flow control trigger occurred. This bit is write one to clear.
  [26:24] TORF_PRI — The lowest priority that caused top of receive FIFO flow control trigger since the last write to clear. This field is write 0x7 to clear.
  [23:16] TX_PFC_FLOW_ACT — Transmit Priority Based Flow Control Active (priority 7 down to 0)
  [15:8] RX_PFC_FLOW_ACT — Receive Priority Based Flow Control Active (priority 7 down to 0)
  [6] EXT_RX_FLOW_EN — External Transmit Flow Control Enable
  [5] EXT_TX_FLOW_EN — External Receive Flow Control Enable
  [4] EXT_GIG — External GIG mode
  [3] EXT_FULLDUPLEX — External Fullduplex
  [1] RX_FLOW_ACT — Receive Flow Control Active
  [0] TX_FLOW_ACT — Transmit Flow Control Active
0x22338 CPSW_NUSS_VBUSP_PN_MAC_SOFT_RESET_REG — Enet Port N Mac Soft Reset
  [0] SOFT_RESET — Software reset
0x2233C CPSW_NUSS_VBUSP_PN_MAC_BOFFTEST_REG access per field — Enet Port N Mac Backoff Test
  [30:26] PACEVAL rw — Pacing Register Current Value
  [25:16] RNDNUM rw — Backoff Random Number Generator
  [15:12] COLL_COUNT ro — Collision Count
  [9:0] TX_BACKOFF ro — Backoff Count
0x22340 CPSW_NUSS_VBUSP_PN_MAC_RX_PAUSETIMER_REG — Enet Port N 802.3 Receive Pause Timer
  [15:0] RX_PAUSETIMER — RX Pause Timer Value
0x22350 CPSW_NUSS_VBUSP_PN_MAC_RXN_PAUSETIMER_REG — Enet Port N PFC Priority P Rx Pause Timer
  [15:0] RX_PAUSETIMER — RX Pause Timer Value
0x22370 CPSW_NUSS_VBUSP_PN_MAC_TX_PAUSETIMER_REG — Enet Port N 802.3 Tx Pause Timer
  [15:0] TX_PAUSETIMER — TX Pause Timer Value
0x22380 CPSW_NUSS_VBUSP_PN_MAC_TXN_PAUSETIMER_REG — Enet Port N PFC Priority P Tx Pause Timer
  [15:0] TX_PAUSETIMER — TX Pause Timer Value
0x223A0 CPSW_NUSS_VBUSP_PN_MAC_EMCONTROL_REG — Enet Port N Emulation Control
  [1] SOFT — Emulation Soft Bit
  [0] FREE — Emulation Free Bit
0x223A4 CPSW_NUSS_VBUSP_PN_MAC_TX_GAP_REG reset 0xC — Enet Port N Tx Inter Packet Gap
  [15:0] TX_GAP — Transmit Inter-Packet Gap
0x223A8 CPSW_NUSS_VBUSP_PN_MAC_PORT_CONFIG ro reset 0x204 — Enet Port N Port Configuration
  [9] IET — IET support
  [8] XGMII — XGMII support
  [7:0] INTERVLAN_ROUTES — The number of InterVLAN routes
0x223AC CPSW_NUSS_VBUSP_PN_INTERVLAN_OPX_POINTER_REG — Enet Port N Tx Egress InterVLAN Operation Pointer
  [2:0] POINTER — InterVLAN location pointer: This field points to the InterVLAN location that will be read/written by accesses to Enet_Pn_InterVLANx_A/B.
0x223B0 CPSW_NUSS_VBUSP_PN_INTERVLAN_OPX_A_REG — Enet Port N Tx Egress InterVLAN A
  [31:24] DA_23_16 — Destination Address bits 23:16
  [23:16] DA_31_24 — Destination Address bits 31:24
  [15:8] DA_39_32 — Destination Address bits 39:32
  [7:0] DA_47_40 — Destination Address bits 47:40
0x223B4 CPSW_NUSS_VBUSP_PN_INTERVLAN_OPX_B_REG — Enet Port N Tx Egress InterVLAN B
  [31:24] SA_39_32 — Source Address bits 39:32
  [23:16] SA_47_40 — Source Address bits 47:40
  [15:8] DA_7_0 — Destination Address bits 7:0
  [7:0] DA_15_8 — Destination Address bits 15:8
0x223B8 CPSW_NUSS_VBUSP_PN_INTERVLAN_OPX_C_REG — Enet Port N Tx Egress InterVLAN C
  [31:24] SA_7_0 — Source Address bits 7:0
  [23:16] SA_15_8 — Source Address bits 15:8
  [15:8] SA_23_16 — Source Address bits 23:16
  [7:0] SA_31_24 — Source Address bits 31:24
0x223BC CPSW_NUSS_VBUSP_PN_INTERVLAN_OPX_D_REG — Enet Port N Tx Egress InterVLAN D
  [15] DECREMENT_TTL — Decrement Time To Live: When set, the Time To Live (TTL) field in the header is decremented.
  [14] DEST_FORCE_UNTAGGED_EGRESS — Destination VLAN Force Untagged Egress: When set, this bit indicates that the VLAN should be removed on egress for the routed packet.
  [13] REPLACE_DA_SA — Replace Destination Address and Source Address: When set this bit indicates that the routed packet destination address should be replaced by da[47:0] and the source address should be replaced by sa[47:0].
  [12] REPLACE_VID — Replace VLAN ID: When set this bit indicates that the VLAN ID should be replaced for the routed packet.
  [11:0] VID — VLAN ID
0x32000 CPSW_NUSS_VBUSP_FETCH_LOC — These are the RAM locations for one ethernet port
  [21:0] LOC — RAM Location
0x3A000 CPSW_NUSS_VBUSP_RXGOODFRAMES — Total number of good frames received
  [31:0] COUNT
0x3A004 CPSW_NUSS_VBUSP_RXBROADCASTFRAMES — Total number of good broadcast frames received
  [31:0] COUNT
0x3A008 CPSW_NUSS_VBUSP_RXMULTICASTFRAMES — Total number of good multicast frames received
  [31:0] COUNT
0x3A010 CPSW_NUSS_VBUSP_RXCRCERRORS — Total number of CRC errors frames received
  [31:0] COUNT
0x3A018 CPSW_NUSS_VBUSP_RXOVERSIZEDFRAMES — Total number of oversized frames received
  [31:0] COUNT
0x3A020 CPSW_NUSS_VBUSP_RXUNDERSIZEDFRAMES — Total number of undersized frames received
  [31:0] COUNT
0x3A024 CPSW_NUSS_VBUSP_RXFRAGMENTS — Total number of fragmented frames received
  [31:0] COUNT
0x3A028 CPSW_NUSS_VBUSP_ALE_DROP — Total number of frames dropped by the ALE
  [31:0] COUNT
0x3A02C CPSW_NUSS_VBUSP_ALE_OVERRUN_DROP — Total number of overrun frames dropped by the ALE
  [31:0] COUNT
0x3A030 CPSW_NUSS_VBUSP_RXOCTETS — Total number of received bytes in good frames
  [31:0] COUNT
0x3A034 CPSW_NUSS_VBUSP_TXGOODFRAMES — Total number of good frames transmitted
  [31:0] COUNT
0x3A038 CPSW_NUSS_VBUSP_TXBROADCASTFRAMES — Total number of good broadcast frames transmitted
  [31:0] COUNT
0x3A03C CPSW_NUSS_VBUSP_TXMULTICASTFRAMES — Total number of good multicast frames transmitted
  [31:0] COUNT
0x3A064 CPSW_NUSS_VBUSP_TXOCTETS — Total number of bytes in all good frames transmitted
  [31:0] COUNT
0x3A068 CPSW_NUSS_VBUSP_OCTETFRAMES64 — Total number of 64-byte frames received and transmitted
  [31:0] COUNT
0x3A06C CPSW_NUSS_VBUSP_OCTETFRAMES65T127 — Total number of frames of size 65 to 127 bytes received and transmitted
  [31:0] COUNT
0x3A070 CPSW_NUSS_VBUSP_OCTETFRAMES128T255 — Total number of frames of size 128 to 255 bytes received and transmitted
  [31:0] COUNT
0x3A074 CPSW_NUSS_VBUSP_OCTETFRAMES256T511 — Total number of frames of size 256 to 511 bytes received and transmitted
  [31:0] COUNT
0x3A078 CPSW_NUSS_VBUSP_OCTETFRAMES512T1023 — Total number of frames of size 512 to 1023 bytes received and transmitted
  [31:0] COUNT
0x3A07C CPSW_NUSS_VBUSP_OCTETFRAMES1024TUP — Total number of frames of size 1024 to rx_maxlen bytes received and 1024 bytes or greater transmitted
  [31:0] COUNT
0x3A080 CPSW_NUSS_VBUSP_NETOCTETS — Total number of bytes received and transmitted
  [31:0] COUNT
0x3A084 CPSW_NUSS_VBUSP_RX_BOTTOM_OF_FIFO_DROP — Receive Bottom of FIFO Drop
  [31:0] COUNT
0x3A088 CPSW_NUSS_VBUSP_PORTMASK_DROP — Total number of dropped frames received due to portmask
  [31:0] COUNT
0x3A08C CPSW_NUSS_VBUSP_RX_TOP_OF_FIFO_DROP — Receive Top of FIFO Drop
  [31:0] COUNT
0x3A090 CPSW_NUSS_VBUSP_ALE_RATE_LIMIT_DROP — Total number of dropped frames due to ALE Rate Limiting
  [31:0] COUNT
0x3A094 CPSW_NUSS_VBUSP_ALE_VID_INGRESS_DROP — Total number of dropped frames due to ALE VID Ingress
  [31:0] COUNT
0x3A098 CPSW_NUSS_VBUSP_ALE_DA_EQ_SA_DROP — Total number of dropped frames due to DA=SA
  [31:0] COUNT
0x3A09C CPSW_NUSS_VBUSP_ALE_BLOCK_DROP — Total number of dropped frames due to ALE Block Mode
  [31:0] COUNT
0x3A0A0 CPSW_NUSS_VBUSP_ALE_SECURE_DROP — Total number of dropped frames due to ALE Secure Mode
  [31:0] COUNT
0x3A0A4 CPSW_NUSS_VBUSP_ALE_AUTH_DROP — Total number of dropped frames due to ALE Authentication
  [31:0] COUNT
0x3A0A8 CPSW_NUSS_VBUSP_ALE_UNKN_UNI — ALE Receive Unknown Unicast
  [31:0] COUNT
0x3A0AC CPSW_NUSS_VBUSP_ALE_UNKN_UNI_BCNT — ALE Receive Unknown Unicast Bytecount
  [31:0] COUNT
0x3A0B0 CPSW_NUSS_VBUSP_ALE_UNKN_MLT — ALE Receive Unknown Multicast
  [31:0] COUNT
0x3A0B4 CPSW_NUSS_VBUSP_ALE_UNKN_MLT_BCNT — ALE Receive Unknown Multicast Bytecount
  [31:0] COUNT
0x3A0B8 CPSW_NUSS_VBUSP_ALE_UNKN_BRD — ALE Receive Unknown Broadcast
  [31:0] COUNT
0x3A0BC CPSW_NUSS_VBUSP_ALE_UNKN_BRD_BCNT — ALE Receive Unknown Broadcast Bytecount
  [31:0] COUNT
0x3A0C0 CPSW_NUSS_VBUSP_ALE_POL_MATCH — ALE Policer Matched
  [31:0] COUNT
0x3A0C4 CPSW_NUSS_VBUSP_ALE_POL_MATCH_RED — ALE Policer Matched and Condition Red
  [31:0] COUNT
0x3A0C8 CPSW_NUSS_VBUSP_ALE_POL_MATCH_YELLOW — ALE Policer Matched and Condition Yellow
  [31:0] COUNT
0x3A0CC CPSW_NUSS_VBUSP_ALE_MULT_SA_DROP — ALE Multicast Source Address Drop
  [31:0] COUNT — ALE Multicast Source Address drop
0x3A0D0 CPSW_NUSS_VBUSP_ALE_DUAL_VLAN_DROP — ALE Dual VLAN Drop
  [31:0] COUNT — ALE Dual VLAN drop
0x3A0D4 CPSW_NUSS_VBUSP_ALE_LEN_ERROR_DROP — ALE Length Error Drop
  [31:0] COUNT — ALE Length Error drop
0x3A0D8 CPSW_NUSS_VBUSP_ALE_IP_NEXT_HDR_DROP — ALE IP Next Header Drop
  [31:0] COUNT — ALE Next Header drop
0x3A0DC CPSW_NUSS_VBUSP_ALE_IPV4_FRAG_DROP — ALE IPV4 Frag Drop
  [31:0] COUNT — ALE IPV4 Fragment drop
0x3A140 CPSW_NUSS_VBUSP_IET_RX_ASSEMBLY_ERROR_REG — IET Receive Assembly Error
  [31:0] IET_RX_ASSEMBLY_ERROR
0x3A144 CPSW_NUSS_VBUSP_IET_RX_ASSEMBLY_OK_REG — IET Receive Assembly Ok
  [31:0] IET_RX_ASSEMBLY_OK
0x3A148 CPSW_NUSS_VBUSP_IET_RX_SMD_ERROR_REG — IET Receive Smd Error
  [31:0] IET_RX_SMD_ERROR
0x3A14C CPSW_NUSS_VBUSP_IET_RX_FRAG_REG — IET Receive Frag
  [31:0] IET_RX_FRAG
0x3A150 CPSW_NUSS_VBUSP_IET_TX_HOLD_REG — IET Transmit Hold
  [31:0] IET_TX_HOLD
0x3A154 CPSW_NUSS_VBUSP_IET_TX_FRAG_REG — IET Transmit Frag
  [31:0] IET_TX_FRAG
0x3A17C CPSW_NUSS_VBUSP_TX_MEMORY_PROTECT_ERROR — Transmit Memory Protect CRC Error
  [7:0] COUNT
0x3A200 CPSW_NUSS_VBUSP_RXGOODFRAMES — Total number of good frames received
  [31:0] COUNT
0x3A204 CPSW_NUSS_VBUSP_RXBROADCASTFRAMES — Total number of good broadcast frames received
  [31:0] COUNT
0x3A208 CPSW_NUSS_VBUSP_RXMULTICASTFRAMES — Total number of good multicast frames received
  [31:0] COUNT
0x3A20C CPSW_NUSS_VBUSP_RXPAUSEFRAMES — Total number of pause frames received
  [31:0] COUNT
0x3A210 CPSW_NUSS_VBUSP_RXCRCERRORS — Total number of CRC errors frames received
  [31:0] COUNT
0x3A214 CPSW_NUSS_VBUSP_RXALIGNCODEERRORS — Total number of alignment/code errors received
  [31:0] COUNT
0x3A218 CPSW_NUSS_VBUSP_RXOVERSIZEDFRAMES — Total number of oversized frames received
  [31:0] COUNT
0x3A21C CPSW_NUSS_VBUSP_RXJABBERFRAMES — Total number of jabber frames received
  [31:0] COUNT
0x3A220 CPSW_NUSS_VBUSP_RXUNDERSIZEDFRAMES — Total number of undersized frames received
  [31:0] COUNT
0x3A224 CPSW_NUSS_VBUSP_RXFRAGMENTS — Total number of fragmented frames received
  [31:0] COUNT
0x3A228 CPSW_NUSS_VBUSP_ALE_DROP — Total number of frames dropped by the ALE
  [31:0] COUNT
0x3A22C CPSW_NUSS_VBUSP_ALE_OVERRUN_DROP — Total number of overrun frames dropped by the ALE
  [31:0] COUNT
0x3A230 CPSW_NUSS_VBUSP_RXOCTETS — Total number of received bytes in good frames
  [31:0] COUNT
0x3A234 CPSW_NUSS_VBUSP_TXGOODFRAMES — Total number of good frames transmitted
  [31:0] COUNT
0x3A238 CPSW_NUSS_VBUSP_TXBROADCASTFRAMES — Total number of good broadcast frames transmitted
  [31:0] COUNT
0x3A23C CPSW_NUSS_VBUSP_TXMULTICASTFRAMES — Total number of good multicast frames transmitted
  [31:0] COUNT
0x3A240 CPSW_NUSS_VBUSP_TXPAUSEFRAMES — Total number of pause frames transmitted
  [31:0] COUNT
0x3A244 CPSW_NUSS_VBUSP_TXDEFERREDFRAMES — Total number of deferred frames transmitted
  [31:0] COUNT
0x3A248 CPSW_NUSS_VBUSP_TXCOLLISIONFRAMES — Total number of transmitted frames experiencing a collision
  [31:0] COUNT
0x3A24C CPSW_NUSS_VBUSP_TXSINGLECOLLFRAMES — Total number of transmitted frames experiencing a single collision
  [31:0] COUNT
0x3A250 CPSW_NUSS_VBUSP_TXMULTCOLLFRAMES — Total number of transmitted frames experiencing multiple collisions
  [31:0] COUNT
0x3A254 CPSW_NUSS_VBUSP_TXEXCESSIVECOLLISIONS — Total number of transmitted frames abandoned due to excessive collisions
  [31:0] COUNT
0x3A258 CPSW_NUSS_VBUSP_TXLATECOLLISIONS — Total number of transmitted frames abandoned due to a late collision
  [31:0] COUNT
0x3A25C CPSW_NUSS_VBUSP_RXIPGERROR — Total number of receive inter-packet gap errors (10G only)
  [31:0] COUNT
0x3A260 CPSW_NUSS_VBUSP_TXCARRIERSENSEERRORS — Total number of transmitted frames that experienced a carrier loss
  [31:0] COUNT
0x3A264 CPSW_NUSS_VBUSP_TXOCTETS — Total number of bytes in all good frames transmitted
  [31:0] COUNT
0x3A268 CPSW_NUSS_VBUSP_OCTETFRAMES64 — Total number of 64-byte frames received and transmitted
  [31:0] COUNT
0x3A26C CPSW_NUSS_VBUSP_OCTETFRAMES65T127 — Total number of frames of size 65 to 127 bytes received and transmitted
  [31:0] COUNT
0x3A270 CPSW_NUSS_VBUSP_OCTETFRAMES128T255 — Total number of frames of size 128 to 255 bytes received and transmitted
  [31:0] COUNT
0x3A274 CPSW_NUSS_VBUSP_OCTETFRAMES256T511 — Total number of frames of size 256 to 511 bytes received and transmitted
  [31:0] COUNT
0x3A278 CPSW_NUSS_VBUSP_OCTETFRAMES512T1023 — Total number of frames of size 512 to 1023 bytes received and transmitted
  [31:0] COUNT
0x3A27C CPSW_NUSS_VBUSP_OCTETFRAMES1024TUP — Total number of frames of size 1024 to rx_maxlen bytes received and 1024 bytes or greater transmitted
  [31:0] COUNT
0x3A280 CPSW_NUSS_VBUSP_NETOCTETS — Total number of bytes received and transmitted
  [31:0] COUNT
0x3A284 CPSW_NUSS_VBUSP_RX_BOTTOM_OF_FIFO_DROP — Receive Bottom of FIFO Drop
  [31:0] COUNT
0x3A288 CPSW_NUSS_VBUSP_PORTMASK_DROP — Total number of dropped frames received due to portmask
  [31:0] COUNT
0x3A28C CPSW_NUSS_VBUSP_RX_TOP_OF_FIFO_DROP — Receive Top of FIFO Drop
  [31:0] COUNT
0x3A290 CPSW_NUSS_VBUSP_ALE_RATE_LIMIT_DROP — Total number of dropped frames due to ALE Rate Limiting
  [31:0] COUNT
0x3A294 CPSW_NUSS_VBUSP_ALE_VID_INGRESS_DROP — Total number of dropped frames due to ALE VID Ingress
  [31:0] COUNT
0x3A298 CPSW_NUSS_VBUSP_ALE_DA_EQ_SA_DROP — Total number of dropped frames due to DA=SA
  [31:0] COUNT
0x3A29C CPSW_NUSS_VBUSP_ALE_BLOCK_DROP — Total number of dropped frames due to ALE Block Mode
  [31:0] COUNT
0x3A2A0 CPSW_NUSS_VBUSP_ALE_SECURE_DROP — Total number of dropped frames due to ALE Secure Mode
  [31:0] COUNT
0x3A2A4 CPSW_NUSS_VBUSP_ALE_AUTH_DROP — Total number of dropped frames due to ALE Authentication
  [31:0] COUNT
0x3A2A8 CPSW_NUSS_VBUSP_ALE_UNKN_UNI — ALE Receive Unknown Unicast
  [31:0] COUNT
0x3A2AC CPSW_NUSS_VBUSP_ALE_UNKN_UNI_BCNT — ALE Receive Unknown Unicast Bytecount
  [31:0] COUNT
0x3A2B0 CPSW_NUSS_VBUSP_ALE_UNKN_MLT — ALE Receive Unknown Multicast
  [31:0] COUNT
0x3A2B4 CPSW_NUSS_VBUSP_ALE_UNKN_MLT_BCNT — ALE Receive Unknown Multicast Bytecount
  [31:0] COUNT
0x3A2B8 CPSW_NUSS_VBUSP_ALE_UNKN_BRD — ALE Receive Unknown Broadcast
  [31:0] COUNT
